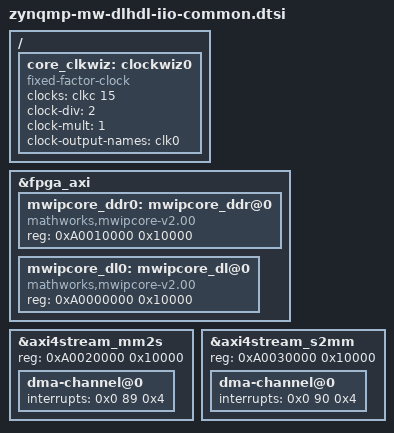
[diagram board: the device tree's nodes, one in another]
/{
	core_clkwiz: clockwiz0 {
		compatible = "fixed-factor-clock";
		clocks = <&clkc 15>;
		#clock-cells = <1>;
		clock-div = <2>;
		clock-mult = <1>;
		clock-output-names = "clk0";
	};
};
&fpga_axi {
		mwipcore_ddr0: mwipcore_ddr@0 {
			compatible = "mathworks,mwipcore-v2.00";
			reg = <0xA0010000 0x10000>;
		};
};

&fpga_axi {
		mwipcore_dl0: mwipcore_dl@0 {
			compatible = "mathworks,mwipcore-v2.00";
			reg = <0xA0000000 0x10000>;
		};
};
#include "mw-axistream-iio-common.h"
#include "xilinx-mw-axistream-dma.h"

#undef MW_MM2S_DATAFMT
#undef MW_S2MM_DATAFMT
#undef XLNX_MM2S_DATAWIDTH
#undef XLNX_S2MM_DATAWIDTH

#define MW_MM2S_DATAFMT "u32/32>>0"
#define MW_S2MM_DATAFMT "u32/32>>0"
#define XLNX_MM2S_DATAWIDTH <0x40>
#define XLNX_S2MM_DATAWIDTH <0x40>

#include "zynqmp-mw-cma.dtsi"
#include "xilinx-mw-dlhdl-iio-common.dtsi"

&axi4stream_mm2s {
	reg = <0xA0020000 0x10000>;
	dma-channel@0  {
		interrupts = <0x0 89 0x4>;
	};
};
&axi4stream_s2mm {
	reg = <0xA0030000 0x10000>;
	dma-channel@0  {
		interrupts = <0x0 90 0x4>;
	};
};
/delete-node/ &mwipcore0;

